# MIMXRT1061 register map
Vendor: nxp.com; File version: 1.0
CPU: CM7 r0p1, little endian, MPU, FPU, VTOR, 4 interrupt priority bits
Registers are 32-bit, read-write, reset 0x0 unless marked. A register's access mark holds for its fields unless they carry their own. Offsets are from the block's base; [hi:lo] are bit positions; {n}, {i} and the like mark numbered series; 'fields as' and 'values as' point back to an identical list.

## SAI1 — SAI
Base 0x40384000
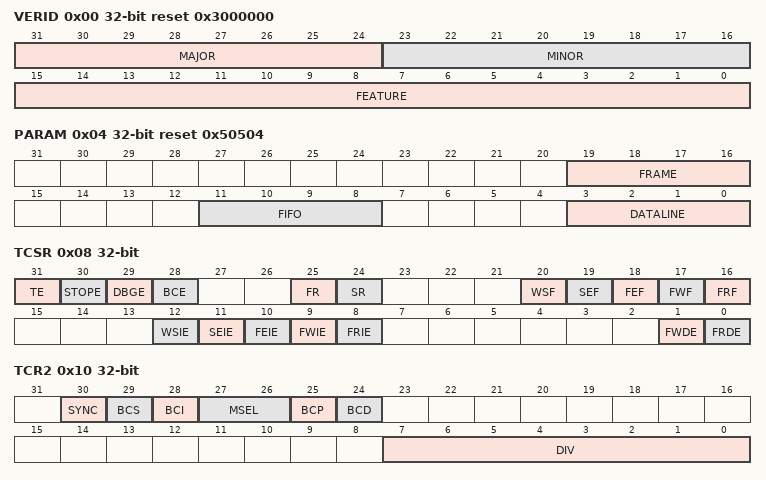
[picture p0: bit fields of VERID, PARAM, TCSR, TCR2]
0x00 VERID ro reset 0x3000000 — Version ID
  [31:24] MAJOR — Major Version Number
  [23:16] MINOR — Minor Version Number
  [15:0] FEATURE — Feature Specification Number
    0=STD (Standard feature set.)
0x04 PARAM ro reset 0x50504 — Parameter
  [19:16] FRAME — Frame Size
  [11:8] FIFO — FIFO Size
  [3:0] DATALINE — Number of Datalines
0x08 TCSR — Transmit Control
  [31] TE — Transmitter Enable
    0=DISABLE (Transmitter is disabled.); 1=ENABLE (Transmitter is enabled, or transmitter has been disabled and has not yet reached end of frame.)
  [30] STOPE — Stop Enable
    0=DISABLE (Transmitter disabled in Stop mode.); 1=ENABLE (Transmitter enabled in Stop mode.)
  [29] DBGE — Debug Enable
    0=DISABLE (Transmitter is disabled in Debug mode, after completing the current frame.); 1=ENABLE (Transmitter is enabled in Debug mode.)
  [28] BCE — Bit Clock Enable
    0=DISABLE (Transmit bit clock is disabled.); 1=ENABLE (Transmit bit clock is enabled.)
  [25] FR — FIFO Reset
    0=NO_EFFECT; 1=RESET (FIFO reset.)
  [24] SR — Software Reset
    0=DISABLE (No effect.); 1=ENABLE (Software reset.)
  [20] WSF write-1-clears — Word Start Flag
    0=NO_FLAG (Start of word not detected.); 1=FLAG (Start of word detected.)
  [19] SEF write-1-clears — Sync Error Flag
    0=NO_FLAG (Sync error not detected.); 1=FLAG (Frame sync error detected.)
  [18] FEF write-1-clears — FIFO Error Flag
    0=NO_FLAG (Transmit underrun not detected.); 1=FLAG (Transmit underrun detected.)
  [17] FWF ro — FIFO Warning Flag
    0=DISABLE (No enabled transmit FIFO is empty.); 1=ENABLE (Enabled transmit FIFO is empty.)
  [16] FRF ro — FIFO Request Flag
    0=NO_FLAG (Transmit FIFO watermark has not been reached.); 1=FLAG (Transmit FIFO watermark has been reached.)
  [12] WSIE — Word Start Interrupt Enable
    0=DISABLE (Disables interrupt.); 1=ENABLE (Enables interrupt.)
  [11] SEIE — Sync Error Interrupt Enable
    values as WSIE
  [10] FEIE — FIFO Error Interrupt Enable
    0=DISABLE (Disables the interrupt.); 1=ENABLE (Enables the interrupt.)
  [9] FWIE — FIFO Warning Interrupt Enable
    values as FEIE
  [8] FRIE — FIFO Request Interrupt Enable
    values as FEIE
  [1] FWDE — FIFO Warning DMA Enable
    0=DISABLE (Disables the DMA request.); 1=ENABLE (Enables the DMA request.)
  [0] FRDE — FIFO Request DMA Enable
    values as FWDE
0x0C TCR1 — Transmit Configuration 1
  [4:0] TFW — Transmit FIFO Watermark
0x10 TCR2 — Transmit Configuration 2
  [30] SYNC — Synchronous Mode
    0=ASYNC (Asynchronous mode.); 1=SYNC_W_RX (Synchronous with receiver.)
  [29] BCS — Bit Clock Swap
    0=DISABLE (Use the normal bit clock source.); 1=ENABLE (Swap the bit clock source.)
  [28] BCI — Bit Clock Input
    0=DISABLE (No effect.); 1=ENABLE (Internal logic is clocked as if bit clock was externally generated.)
  [27:26] MSEL — MCLK Select
    0=BUS_CLOCK (Bus Clock selected.); 1=MCLK1 (Master Clock (MCLK) 1 option selected.); 2=MCLK2 (Master Clock (MCLK) 2 option selected.); 3=MCLK3 (Master Clock (MCLK) 3 option selected.)
  [25] BCP — Bit Clock Polarity
    0=ACTIVE_HIGH (Bit clock is active high with drive outputs on rising edge and sample inputs on falling edge.); 1=ACTIVE_LOW (Bit clock is active low with drive outputs on falling edge and sample inputs on rising edge.)
  [24] BCD — Bit Clock Direction
    0=EXT_IN_SLAVE (Bit clock is generated externally in Slave mode.); 1=INT_IN_MASTER (Bit clock is generated internally in Master mode.)
  [7:0] DIV — Bit Clock Divide
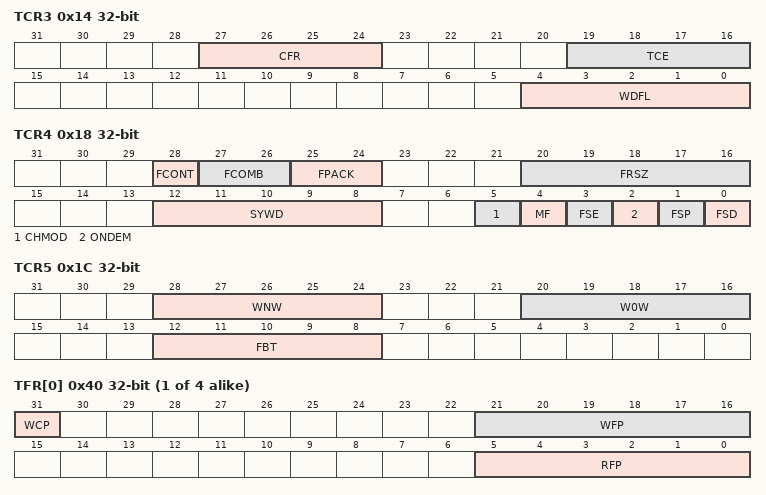
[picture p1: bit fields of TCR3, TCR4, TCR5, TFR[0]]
0x14 TCR3 — Transmit Configuration 3
  [27:24] CFR — Channel FIFO Reset
  [19:16] TCE — Transmit Channel Enable
  [4:0] WDFL — Word Flag Configuration
0x18 TCR4 — Transmit Configuration 4
  [28] FCONT — FIFO Continue on Error
    0=DISABLE (On FIFO error, the SAI will continue from the start of the next frame after the FIFO error flag has been cleared.); 1=ENABLE (On FIFO error, the SAI will continue from the same word that caused the FIFO error to set after the FIFO warning flag has been cleared.)
  [27:26] FCOMB — FIFO Combine Mode
    0=DISABLED (FIFO combine mode disabled.); 1=ENABLED_ON_FIFO_READS (FIFO combine mode enabled on FIFO reads (from transmit shift registers).); 2=ENABLED_ON_FIFO_WRITES (FIFO combine mode enabled on FIFO writes (by software).); 3=ENABLED_ON_FIFO_READS_WRITES (FIFO combine mode enabled on FIFO reads (from transmit shift registers) and writes (by software).)
  [25:24] FPACK — FIFO Packing Mode
    0=DISABLED (FIFO packing is disabled.); 2=EIGHT_BIT_FIFO_PACKING (8-bit FIFO packing is enabled.); 3=SIXTEEN_BIT_FIFO_PACKING (16-bit FIFO packing is enabled.)
  [20:16] FRSZ — Frame size
  [12:8] SYWD — Sync Width
  [5] CHMOD — Channel Mode
    0=TDM_MODE (TDM mode, transmit data pins are tri-stated when slots are masked or channels are disabled.); 1=OUTPUT_MODE (Output mode, transmit data pins are never tri-stated and will output zero when slots are masked or channels are disabled.)
  [4] MF — MSB First
    0=DISABLE (LSB is transmitted first.); 1=ENABLE (MSB is transmitted first.)
  [3] FSE — Frame Sync Early
    0=DISABLE (Frame sync asserts with the first bit of the frame.); 1=ENABLE (Frame sync asserts one bit before the first bit of the frame.)
  [2] ONDEM — On Demand Mode
    0=CONTINUOUS_FRAME_SYNC (Internal frame sync is generated continuously.); 1=ON_DEMAND_FRAME_SYNC (Internal frame sync is generated when the FIFO warning flag is clear.)
  [1] FSP — Frame Sync Polarity
    0=ACTIVE_HIGH (Frame sync is active high.); 1=ACTIVE_LOW (Frame sync is active low.)
  [0] FSD — Frame Sync Direction
    0=EXT_IN_SLAVE_MODE (Frame sync is generated externally in Slave mode.); 1=INT_IN_MASTER_MODE (Frame sync is generated internally in Master mode.)
0x1C TCR5 — Transmit Configuration 5
  [28:24] WNW — Word N Width
  [20:16] W0W — Word 0 Width
  [12:8] FBT — First Bit Shifted
{0x20+4i} TDR[{i}] (i=0..3) — Transmit Data
  [31:0] TDR — Transmit Data Register
{0x40+4i} TFR[{i}] (i=0..3) ro — Transmit FIFO
  [31] WCP — Write Channel Pointer
    0=DISABLE (No effect.); 1=ENABLE (FIFO combine is enabled for FIFO writes and this FIFO will be written on the next FIFO write.)
  [21:16] WFP — Write FIFO Pointer
  [5:0] RFP — Read FIFO Pointer
0x60 TMR — Transmit Mask
  [31:0] TWM — Transmit Word Mask
    0=WORD_N_ENABLED (Word N is enabled.); 1=WORD_N_MASKED (Word N is masked. The transmit data pins are tri-stated or drive zero when masked.)
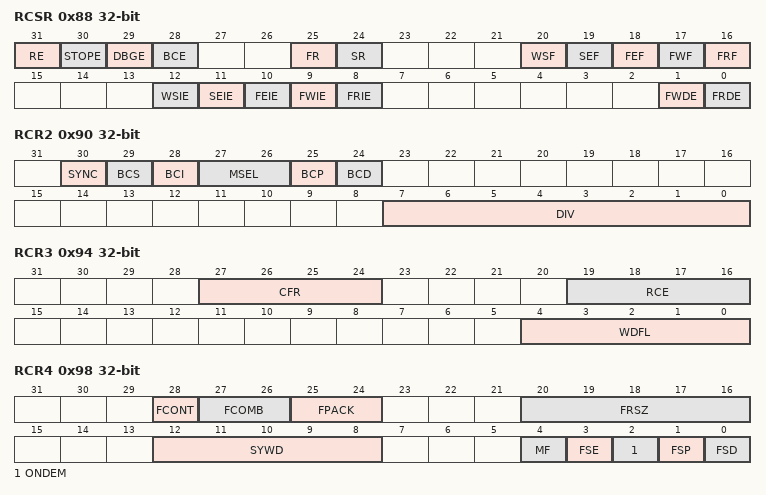
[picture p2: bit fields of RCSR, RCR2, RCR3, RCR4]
0x88 RCSR — Receive Control
  [31] RE — Receiver Enable
    0=DISABLE (Receiver is disabled.); 1=ENABLE (Receiver is enabled, or receiver has been disabled and has not yet reached end of frame.)
  [30] STOPE — Stop Enable
    0=DISABLE (Receiver disabled in Stop mode.); 1=ENABLE (Receiver enabled in Stop mode.)
  [29] DBGE — Debug Enable
    0=DISABLE (Receiver is disabled in Debug mode, after completing the current frame.); 1=ENABLE (Receiver is enabled in Debug mode.)
  [28] BCE — Bit Clock Enable
    0=DISABLE (Receive bit clock is disabled.); 1=ENABLE (Receive bit clock is enabled.)
  [25] FR — FIFO Reset
    0=NO_EFFECT; 1=FIFO_RESET
  [24] SR — Software Reset
    0=NO_EFFECT; 1=SW_RESET (Software reset.)
  [20] WSF write-1-clears — Word Start Flag
    values as TCSR.WSF
  [19] SEF write-1-clears — Sync Error Flag
    values as TCSR.SEF
  [18] FEF write-1-clears — FIFO Error Flag
    0=NO_FLAG (Receive overflow not detected.); 1=FLAG (Receive overflow detected.)
  [17] FWF ro — FIFO Warning Flag
    0=NOT_FULL (No enabled receive FIFO is full.); 1=FULL (Enabled receive FIFO is full.)
  [16] FRF ro — FIFO Request Flag
    0=BELOW_WATERMARK (Receive FIFO watermark not reached.); 1=WATERMARK_REACHED (Receive FIFO watermark has been reached.)
  [12] WSIE — Word Start Interrupt Enable
    values as TCSR.WSIE
  [11] SEIE — Sync Error Interrupt Enable
    values as TCSR.WSIE
  [10] FEIE — FIFO Error Interrupt Enable
    values as TCSR.FEIE
  [9] FWIE — FIFO Warning Interrupt Enable
    values as TCSR.FEIE
  [8] FRIE — FIFO Request Interrupt Enable
    values as TCSR.FEIE
  [1] FWDE — FIFO Warning DMA Enable
    values as TCSR.FWDE
  [0] FRDE — FIFO Request DMA Enable
    values as TCSR.FWDE
0x8C RCR1 — Receive Configuration 1
  [4:0] RFW — Receive FIFO Watermark
0x90 RCR2 — Receive Configuration 2
  [30] SYNC — Synchronous Mode
    0=Asynchronous mode; 1=SYNC_W_TX (Synchronous with transmitter.)
  [29] BCS — Bit Clock Swap
    0=NORMAL (Use the normal bit clock source.); 1=SWAP_BIT_CLK_SOURCE (Swap the bit clock source.)
  [28] BCI — Bit Clock Input
    0=NO_EFFECT; 1=CLOCKED_AS_IF_EXT_GENERATED (Internal logic is clocked as if bit clock was externally generated.)
  [27:26] MSEL — MCLK Select
    values as TCR2.MSEL
  [25] BCP — Bit Clock Polarity
    0=ACTIVE_HIGH (Bit Clock is active high with drive outputs on rising edge and sample inputs on falling edge.); 1=ACTIVE_LOW (Bit Clock is active low with drive outputs on falling edge and sample inputs on rising edge.)
  [24] BCD — Bit Clock Direction
    0=EXT_SLAVE_MODE (Bit clock is generated externally in Slave mode.); 1=INT_MASTER_MODE (Bit clock is generated internally in Master mode.)
  [7:0] DIV — Bit Clock Divide
0x94 RCR3 — Receive Configuration 3
  [27:24] CFR — Channel FIFO Reset
  [19:16] RCE — Receive Channel Enable
  [4:0] WDFL — Word Flag Configuration
0x98 RCR4 — Receive Configuration 4
  [28] FCONT — FIFO Continue on Error
    values as TCR4.FCONT
  [27:26] FCOMB — FIFO Combine Mode
    0=DISABLED (FIFO combine mode disabled.); 1=ENA_ON_FIFO_WRITES (FIFO combine mode enabled on FIFO writes (from receive shift registers).); 2=ENA_ON_FIFO_READS (FIFO combine mode enabled on FIFO reads (by software).); 3=ENA_ON_FIFO_WRITES_READS (FIFO combine mode enabled on FIFO writes (from receive shift registers) and reads (by software).)
  [25:24] FPACK — FIFO Packing Mode
    0=DISABLED (FIFO packing is disabled); 2=EIGHT_BIT_PACKING (8-bit FIFO packing is enabled); 3=SIXTEEN_BIT_PACKING (16-bit FIFO packing is enabled)
  [20:16] FRSZ — Frame Size
  [12:8] SYWD — Sync Width
  [4] MF — MSB First
    0=DISABLE (LSB is received first.); 1=ENABLE (MSB is received first.)
  [3] FSE — Frame Sync Early
    values as TCR4.FSE
  [2] ONDEM — On Demand Mode
    0=DISABLE (Internal frame sync is generated continuously.); 1=ENABLE (Internal frame sync is generated when the FIFO warning flag is clear.)
  [1] FSP — Frame Sync Polarity
    values as TCR4.FSP
  [0] FSD — Frame Sync Direction
    0=EXT_SLAVE_MODE (Frame Sync is generated externally in Slave mode.); 1=INT_MASTER_MODE (Frame Sync is generated internally in Master mode.)
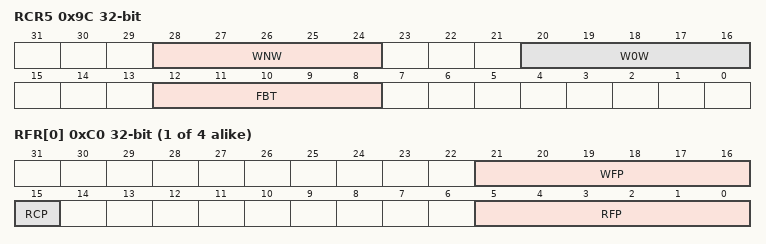
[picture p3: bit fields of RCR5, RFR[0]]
0x9C RCR5 — Receive Configuration 5
  fields as TCR5
{0xA0+4i} RDR[{i}] (i=0..3) ro — Receive Data
  [31:0] RDR — Receive Data Register
{0xC0+4i} RFR[{i}] (i=0..3) ro — Receive FIFO
  [21:16] WFP — Write FIFO Pointer
  [15] RCP — Receive Channel Pointer
    0=DISABLE (No effect.); 1=ENABLE (FIFO combine is enabled for FIFO reads and this FIFO will be read on the next FIFO read.)
  [5:0] RFP — Read FIFO Pointer
0xE0 RMR — Receive Mask
  [31:0] RWM — Receive Word Mask
    0=WORD_N_ENABLED (Word N is enabled.); 1=WORD_N_MASKED (Word N is masked.)

## SAI2 — SAI
Base 0x40388000
Same registers: SAI3 0x4038C000
Registers as SAI1, without TDR[*], TFR[*], RDR[*], RFR[*]; these are added or differ:
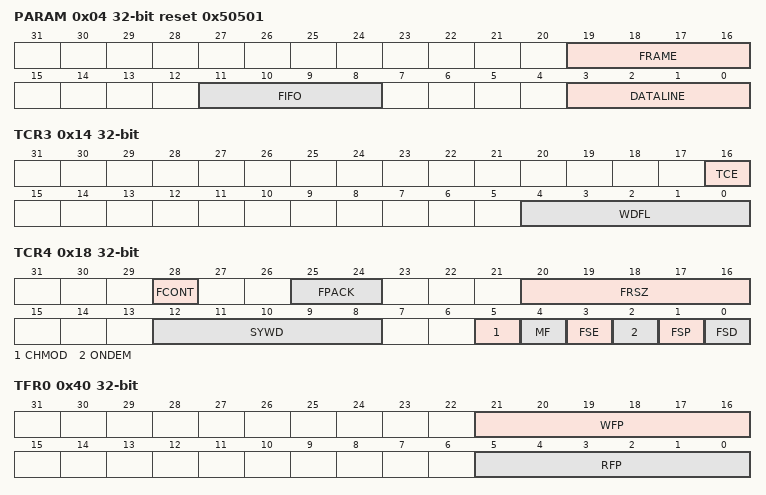
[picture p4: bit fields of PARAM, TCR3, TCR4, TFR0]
0x04 PARAM ro reset 0x50501 — Parameter
  [19:16] FRAME — Frame Size
  [11:8] FIFO — FIFO Size
  [3:0] DATALINE — Number of Datalines
0x14 TCR3 — Transmit Configuration 3
  [16] TCE — Transmit Channel Enable
  [4:0] WDFL — Word Flag Configuration
0x18 TCR4 — Transmit Configuration 4
  [28] FCONT — FIFO Continue on Error
    values as SAI1.TCR4.FCONT
  [25:24] FPACK — FIFO Packing Mode
    0=DISABLED (FIFO packing is disabled.); 2=EIGHT_BIT_FIFO_PACKING (8-bit FIFO packing is enabled.); 3=SIXTEEN_BIT_FIFO_PACKING (16-bit FIFO packing is enabled.)
  [20:16] FRSZ — Frame size
  [12:8] SYWD — Sync Width
  [5] CHMOD — Channel Mode
    values as SAI1.TCR4.CHMOD
  [4] MF — MSB First
    0=DISABLE (LSB is transmitted first.); 1=ENABLE (MSB is transmitted first.)
  [3] FSE — Frame Sync Early
    0=DISABLE (Frame sync asserts with the first bit of the frame.); 1=ENABLE (Frame sync asserts one bit before the first bit of the frame.)
  [2] ONDEM — On Demand Mode
    0=CONTINUOUS_FRAME_SYNC (Internal frame sync is generated continuously.); 1=ON_DEMAND_FRAME_SYNC (Internal frame sync is generated when the FIFO warning flag is clear.)
  [1] FSP — Frame Sync Polarity
    0=ACTIVE_HIGH (Frame sync is active high.); 1=ACTIVE_LOW (Frame sync is active low.)
  [0] FSD — Frame Sync Direction
    0=EXT_IN_SLAVE_MODE (Frame sync is generated externally in Slave mode.); 1=INT_IN_MASTER_MODE (Frame sync is generated internally in Master mode.)
0x20 TDR0 — Transmit Data
  [31:0] TDR — Transmit Data Register
0x40 TFR0 ro — Transmit FIFO
  [21:16] WFP — Write FIFO Pointer
  [5:0] RFP — Read FIFO Pointer
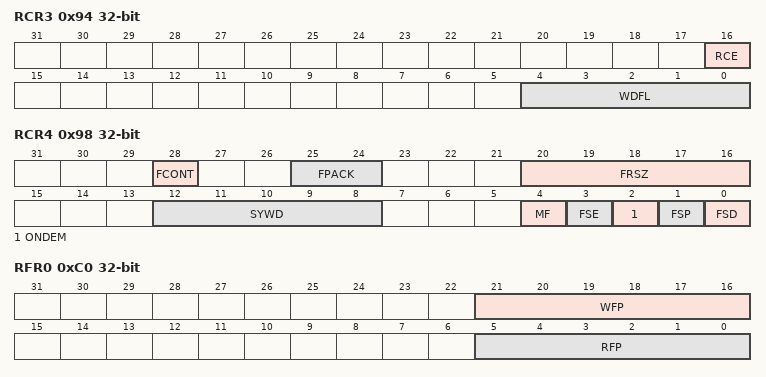
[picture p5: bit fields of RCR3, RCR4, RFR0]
0x94 RCR3 — Receive Configuration 3
  [16] RCE — Receive Channel Enable
  [4:0] WDFL — Word Flag Configuration
0x98 RCR4 — Receive Configuration 4
  [28] FCONT — FIFO Continue on Error
    values as SAI1.TCR4.FCONT
  [25:24] FPACK — FIFO Packing Mode
    0=DISABLED (FIFO packing is disabled); 2=EIGHT_BIT_PACKING (8-bit FIFO packing is enabled); 3=SIXTEEN_BIT_PACKING (16-bit FIFO packing is enabled)
  [20:16] FRSZ — Frame Size
  [12:8] SYWD — Sync Width
  [4] MF — MSB First
    0=DISABLE (LSB is received first.); 1=ENABLE (MSB is received first.)
  [3] FSE — Frame Sync Early
    values as TCR4.FSE
  [2] ONDEM — On Demand Mode
    0=DISABLE (Internal frame sync is generated continuously.); 1=ENABLE (Internal frame sync is generated when the FIFO warning flag is clear.)
  [1] FSP — Frame Sync Polarity
    values as TCR4.FSP
  [0] FSD — Frame Sync Direction
    0=EXT_SLAVE_MODE (Frame Sync is generated externally in Slave mode.); 1=INT_MASTER_MODE (Frame Sync is generated internally in Master mode.)
0xA0 RDR0 ro — Receive Data
  [31:0] RDR — Receive Data Register
0xC0 RFR0 ro — Receive FIFO
  [21:16] WFP — Write FIFO Pointer
  [5:0] RFP — Read FIFO Pointer
